AUTOSAR XML (schema 00048)
package /AdaptiveApplicationSwComponentTypes
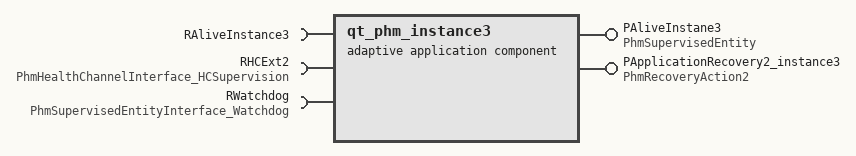
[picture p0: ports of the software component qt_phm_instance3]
  adaptive application sw component type qt_phm_instance3: category=APPLICATION_LEVEL
    require port RAliveInstance3
    provide port PAliveInstane3: provided-interface=PhmSupervisedEntity
    require port RHCExt2: required-interface=PhmHealthChannelInterface_HCSupervision
    provide port PApplicationRecovery2_instance3: provided-interface=PhmRecoveryAction2
    require port RWatchdog: required-interface=PhmSupervisedEntityInterface_Watchdog
package /Executables
  executable qt_phm_instance3
    root sw component prototype rootSwComponentPrototype: application-type=qt_phm_instance3
package /ProcessDesign
  process design qt_phm_instance3: executable=qt_phm_instance3
